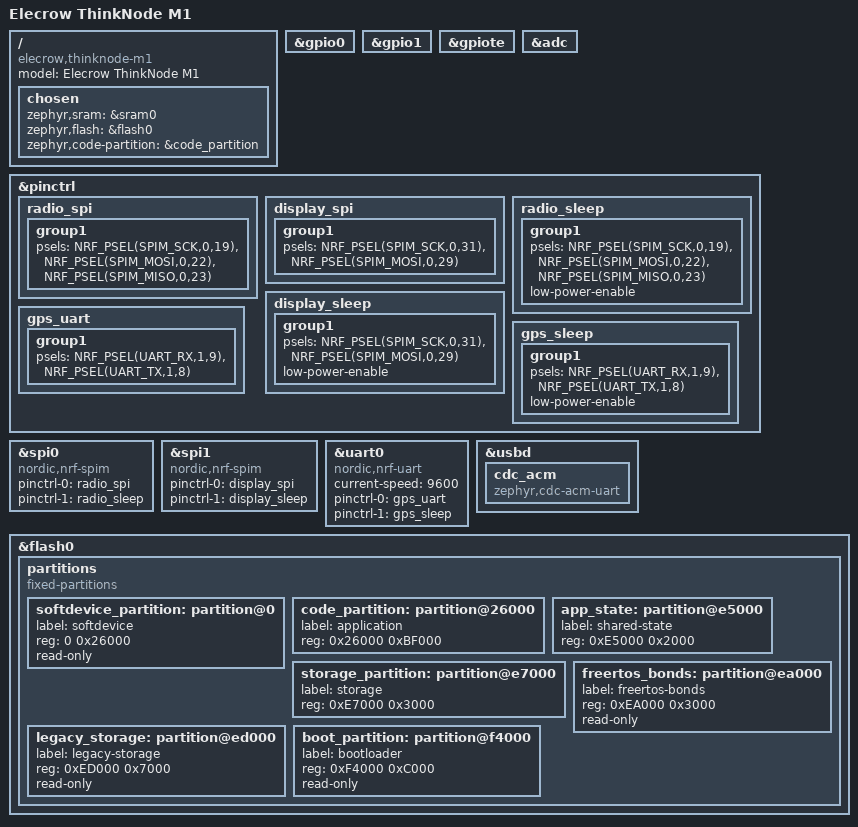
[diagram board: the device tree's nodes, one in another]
/dts-v1/;
#include <nordic/nrf52840_qiaa.dtsi>
#include <zephyr/dt-bindings/pinctrl/nrf-pinctrl.h>
/ {
  model = "Elecrow ThinkNode M1";
  compatible = "elecrow,thinknode-m1";
  chosen {
    zephyr,sram = &sram0;
    zephyr,flash = &flash0;
    zephyr,code-partition = &code_partition;
  };
};
&gpio0 { status = "okay"; };
&gpio1 { status = "okay"; };
&gpiote { status = "okay"; };
&adc { status = "okay"; };
&pinctrl {
  radio_spi: radio_spi { group1 { psels = <NRF_PSEL(SPIM_SCK,0,19)>, <NRF_PSEL(SPIM_MOSI,0,22)>, <NRF_PSEL(SPIM_MISO,0,23)>; }; };
  display_spi: display_spi { group1 { psels = <NRF_PSEL(SPIM_SCK,0,31)>, <NRF_PSEL(SPIM_MOSI,0,29)>; }; };
  radio_sleep: radio_sleep { group1 { psels = <NRF_PSEL(SPIM_SCK,0,19)>, <NRF_PSEL(SPIM_MOSI,0,22)>, <NRF_PSEL(SPIM_MISO,0,23)>; low-power-enable; }; };
  display_sleep: display_sleep { group1 { psels = <NRF_PSEL(SPIM_SCK,0,31)>, <NRF_PSEL(SPIM_MOSI,0,29)>; low-power-enable; }; };
  gps_uart: gps_uart { group1 { psels = <NRF_PSEL(UART_RX,1,9)>, <NRF_PSEL(UART_TX,1,8)>; }; };
  gps_sleep: gps_sleep { group1 { psels = <NRF_PSEL(UART_RX,1,9)>, <NRF_PSEL(UART_TX,1,8)>; low-power-enable; }; };
};
&spi0 { compatible = "nordic,nrf-spim"; status = "okay"; pinctrl-0 = <&radio_spi>; pinctrl-1 = <&radio_sleep>; pinctrl-names = "default", "sleep"; };
&spi1 { compatible = "nordic,nrf-spim"; status = "okay"; pinctrl-0 = <&display_spi>; pinctrl-1 = <&display_sleep>; pinctrl-names = "default", "sleep"; };
&uart0 { compatible = "nordic,nrf-uart"; status = "okay"; current-speed = <9600>;
  pinctrl-0 = <&gps_uart>; pinctrl-1 = <&gps_sleep>; pinctrl-names = "default", "sleep"; };
&usbd { status = "okay"; cdc_acm: cdc_acm { compatible = "zephyr,cdc-acm-uart"; }; };
&flash0 {
  partitions {
    compatible = "fixed-partitions"; #address-cells = <1>; #size-cells = <1>;
    softdevice_partition: partition@0 { label = "softdevice"; reg = <0 0x26000>; read-only; };
    code_partition: partition@26000 { label = "application"; reg = <0x26000 0xBF000>; };
    app_state: partition@e5000 { label = "shared-state"; reg = <0xE5000 0x2000>; };
    storage_partition: partition@e7000 { label = "storage"; reg = <0xE7000 0x3000>; };
    freertos_bonds: partition@ea000 { label = "freertos-bonds"; reg = <0xEA000 0x3000>; read-only; };
    legacy_storage: partition@ed000 { label = "legacy-storage"; reg = <0xED000 0x7000>; read-only; };
    boot_partition: partition@f4000 { label = "bootloader"; reg = <0xF4000 0xC000>; read-only; };
  };
};
